# CY8C5888LTI_LP097 register map
File version: 0.1
Registers are 8-bit, read-write, no defined reset value unless marked. A register's access mark holds for its fields unless they carry their own. Offsets are from the block's base; [hi:lo] are bit positions; 'fields as' and 'values as' point back to an identical list.

## Encoder_4
Base 0x00000000
0x4000640A Encoder_4_COUNTER 24-bit — UDB.A0 - Current Counter Value
0x4000642A Encoder_4_PERIOD 24-bit — UDB.D0 - Assigned Period
0x4000643A Encoder_4_COMPARE 24-bit — UDB.D1 - Assigned Compare Value
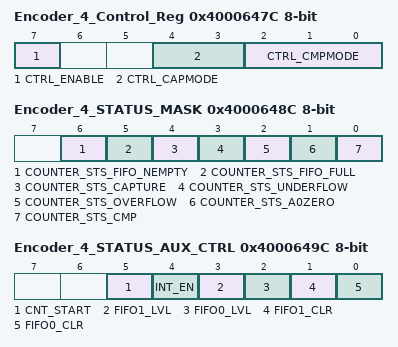
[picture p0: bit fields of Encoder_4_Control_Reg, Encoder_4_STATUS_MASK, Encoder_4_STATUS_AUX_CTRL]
0x4000647C Encoder_4_Control_Reg — UDB Control Register - Assigned Control Register Value
  [7] CTRL_ENABLE — Enable Counter
  [4:3] CTRL_CAPMODE — Capture mode
  [2:0] CTRL_CMPMODE — Compare mode
0x4000648C Encoder_4_STATUS_MASK — UDB Status bits Interrupt Mask Enable Register
  [6] COUNTER_STS_FIFO_NEMPTY — FIFO Not Empty Status
  [5] COUNTER_STS_FIFO_FULL — FIFO Full Status
  [4] COUNTER_STS_CAPTURE — Capture Status
  [3] COUNTER_STS_UNDERFLOW — Underflow status
  [2] COUNTER_STS_OVERFLOW — Overflow status
  [1] COUNTER_STS_A0ZERO — A0 Zero ouput status
  [0] COUNTER_STS_CMP — Compare output status
0x4000649C Encoder_4_STATUS_AUX_CTRL — UDB Auxilliary Control Register
  [5] CNT_START — FIFO0 clear
    0=E_CNT_START0 (Disable counter); 1=E_CNT_START1 (Enable counter)
  [4] INT_EN
    0=E_INT_EN0 (Interrupt disabled); 1=E_INT_EN1 (Interrupt enabled)
  [3] FIFO1_LVL — FIFO level
    0=E_FIFO_LVL_0 (FIFO LVL: input mode: FIFO not full; output mode: FIFO not empty); 1=E_FIFO_LVL_1 (FIFO LVL: input mode: FIFO at least 1/2 empty; output mode: FIFO at least 1/2 full)
  [2] FIFO0_LVL — FIFO level
    values as FIFO1_LVL
  [1] FIFO1_CLR — FIFO1 clear
    0=E_FIFO_CLR_0 (Normal FIFO operation); 1=E_FIFO_CLR_1 (Clear FIFO state)
  [0] FIFO0_CLR — FIFO0 clear
    values as FIFO1_CLR

## Encoder_5
Base 0x00000000
0x4000640D Encoder_5_COUNTER 24-bit — UDB.A0 - Current Counter Value
0x4000642D Encoder_5_PERIOD 24-bit — UDB.D0 - Assigned Period
0x4000643D Encoder_5_COMPARE 24-bit — UDB.D1 - Assigned Compare Value
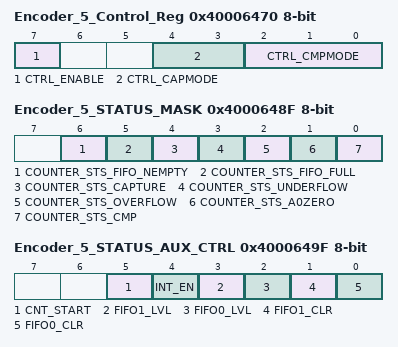
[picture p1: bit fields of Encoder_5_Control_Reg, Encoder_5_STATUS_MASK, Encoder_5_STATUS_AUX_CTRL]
0x40006470 Encoder_5_Control_Reg — UDB Control Register - Assigned Control Register Value
  [7] CTRL_ENABLE — Enable Counter
  [4:3] CTRL_CAPMODE — Capture mode
  [2:0] CTRL_CMPMODE — Compare mode
0x4000648F Encoder_5_STATUS_MASK — UDB Status bits Interrupt Mask Enable Register
  [6] COUNTER_STS_FIFO_NEMPTY — FIFO Not Empty Status
  [5] COUNTER_STS_FIFO_FULL — FIFO Full Status
  [4] COUNTER_STS_CAPTURE — Capture Status
  [3] COUNTER_STS_UNDERFLOW — Underflow status
  [2] COUNTER_STS_OVERFLOW — Overflow status
  [1] COUNTER_STS_A0ZERO — A0 Zero ouput status
  [0] COUNTER_STS_CMP — Compare output status
0x4000649F Encoder_5_STATUS_AUX_CTRL — UDB Auxilliary Control Register
  [5] CNT_START — FIFO0 clear
    0=E_CNT_START0 (Disable counter); 1=E_CNT_START1 (Enable counter)
  [4] INT_EN
    0=E_INT_EN0 (Interrupt disabled); 1=E_INT_EN1 (Interrupt enabled)
  [3] FIFO1_LVL — FIFO level
    0=E_FIFO_LVL_0 (FIFO LVL: input mode: FIFO not full; output mode: FIFO not empty); 1=E_FIFO_LVL_1 (FIFO LVL: input mode: FIFO at least 1/2 empty; output mode: FIFO at least 1/2 full)
  [2] FIFO0_LVL — FIFO level
    values as FIFO1_LVL
  [1] FIFO1_CLR — FIFO1 clear
    0=E_FIFO_CLR_0 (Normal FIFO operation); 1=E_FIFO_CLR_1 (Clear FIFO state)
  [0] FIFO0_CLR — FIFO0 clear
    values as FIFO1_CLR

## Encoder_3
Base 0x00000000
0x40006407 Encoder_3_COUNTER 24-bit — UDB.A0 - Current Counter Value
0x40006427 Encoder_3_PERIOD 24-bit — UDB.D0 - Assigned Period
0x40006437 Encoder_3_COMPARE 24-bit — UDB.D1 - Assigned Compare Value
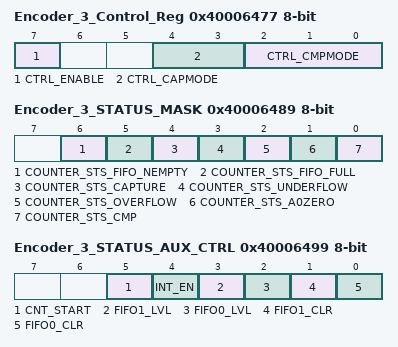
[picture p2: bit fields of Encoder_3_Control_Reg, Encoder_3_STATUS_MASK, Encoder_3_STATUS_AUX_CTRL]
0x40006477 Encoder_3_Control_Reg — UDB Control Register - Assigned Control Register Value
  [7] CTRL_ENABLE — Enable Counter
  [4:3] CTRL_CAPMODE — Capture mode
  [2:0] CTRL_CMPMODE — Compare mode
0x40006489 Encoder_3_STATUS_MASK — UDB Status bits Interrupt Mask Enable Register
  [6] COUNTER_STS_FIFO_NEMPTY — FIFO Not Empty Status
  [5] COUNTER_STS_FIFO_FULL — FIFO Full Status
  [4] COUNTER_STS_CAPTURE — Capture Status
  [3] COUNTER_STS_UNDERFLOW — Underflow status
  [2] COUNTER_STS_OVERFLOW — Overflow status
  [1] COUNTER_STS_A0ZERO — A0 Zero ouput status
  [0] COUNTER_STS_CMP — Compare output status
0x40006499 Encoder_3_STATUS_AUX_CTRL — UDB Auxilliary Control Register
  [5] CNT_START — FIFO0 clear
    0=E_CNT_START0 (Disable counter); 1=E_CNT_START1 (Enable counter)
  [4] INT_EN
    0=E_INT_EN0 (Interrupt disabled); 1=E_INT_EN1 (Interrupt enabled)
  [3] FIFO1_LVL — FIFO level
    0=E_FIFO_LVL_0 (FIFO LVL: input mode: FIFO not full; output mode: FIFO not empty); 1=E_FIFO_LVL_1 (FIFO LVL: input mode: FIFO at least 1/2 empty; output mode: FIFO at least 1/2 full)
  [2] FIFO0_LVL — FIFO level
    values as FIFO1_LVL
  [1] FIFO1_CLR — FIFO1 clear
    0=E_FIFO_CLR_0 (Normal FIFO operation); 1=E_FIFO_CLR_1 (Clear FIFO state)
  [0] FIFO0_CLR — FIFO0 clear
    values as FIFO1_CLR

## Encoder_1
Base 0x00000000
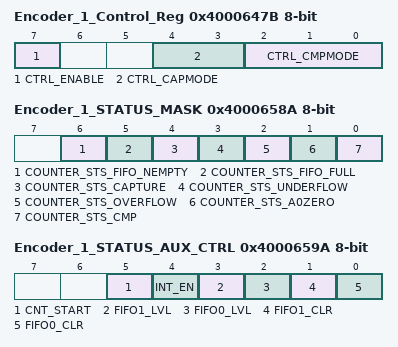
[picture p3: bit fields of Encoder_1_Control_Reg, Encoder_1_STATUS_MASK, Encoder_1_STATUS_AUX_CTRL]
0x4000647B Encoder_1_Control_Reg — UDB Control Register - Assigned Control Register Value
  [7] CTRL_ENABLE — Enable Counter
  [4:3] CTRL_CAPMODE — Capture mode
  [2:0] CTRL_CMPMODE — Compare mode
0x40006508 Encoder_1_COUNTER 24-bit — UDB.A0 - Current Counter Value
0x40006528 Encoder_1_PERIOD 24-bit — UDB.D0 - Assigned Period
0x40006538 Encoder_1_COMPARE 24-bit — UDB.D1 - Assigned Compare Value
0x4000658A Encoder_1_STATUS_MASK — UDB Status bits Interrupt Mask Enable Register
  [6] COUNTER_STS_FIFO_NEMPTY — FIFO Not Empty Status
  [5] COUNTER_STS_FIFO_FULL — FIFO Full Status
  [4] COUNTER_STS_CAPTURE — Capture Status
  [3] COUNTER_STS_UNDERFLOW — Underflow status
  [2] COUNTER_STS_OVERFLOW — Overflow status
  [1] COUNTER_STS_A0ZERO — A0 Zero ouput status
  [0] COUNTER_STS_CMP — Compare output status
0x4000659A Encoder_1_STATUS_AUX_CTRL — UDB Auxilliary Control Register
  [5] CNT_START — FIFO0 clear
    0=E_CNT_START0 (Disable counter); 1=E_CNT_START1 (Enable counter)
  [4] INT_EN
    0=E_INT_EN0 (Interrupt disabled); 1=E_INT_EN1 (Interrupt enabled)
  [3] FIFO1_LVL — FIFO level
    0=E_FIFO_LVL_0 (FIFO LVL: input mode: FIFO not full; output mode: FIFO not empty); 1=E_FIFO_LVL_1 (FIFO LVL: input mode: FIFO at least 1/2 empty; output mode: FIFO at least 1/2 full)
  [2] FIFO0_LVL — FIFO level
    values as FIFO1_LVL
  [1] FIFO1_CLR — FIFO1 clear
    0=E_FIFO_CLR_0 (Normal FIFO operation); 1=E_FIFO_CLR_1 (Clear FIFO state)
  [0] FIFO0_CLR — FIFO0 clear
    values as FIFO1_CLR

## Encoder_2
Base 0x00000000
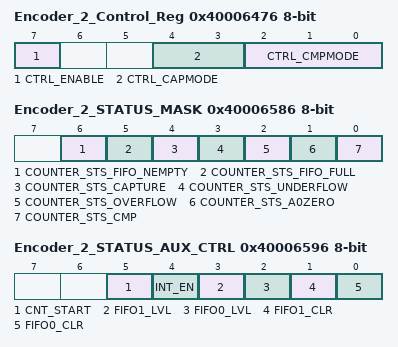
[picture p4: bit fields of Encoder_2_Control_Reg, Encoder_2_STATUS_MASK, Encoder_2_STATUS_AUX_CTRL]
0x40006476 Encoder_2_Control_Reg — UDB Control Register - Assigned Control Register Value
  [7] CTRL_ENABLE — Enable Counter
  [4:3] CTRL_CAPMODE — Capture mode
  [2:0] CTRL_CMPMODE — Compare mode
0x40006504 Encoder_2_COUNTER 24-bit — UDB.A0 - Current Counter Value
0x40006524 Encoder_2_PERIOD 24-bit — UDB.D0 - Assigned Period
0x40006534 Encoder_2_COMPARE 24-bit — UDB.D1 - Assigned Compare Value
0x40006586 Encoder_2_STATUS_MASK — UDB Status bits Interrupt Mask Enable Register
  [6] COUNTER_STS_FIFO_NEMPTY — FIFO Not Empty Status
  [5] COUNTER_STS_FIFO_FULL — FIFO Full Status
  [4] COUNTER_STS_CAPTURE — Capture Status
  [3] COUNTER_STS_UNDERFLOW — Underflow status
  [2] COUNTER_STS_OVERFLOW — Overflow status
  [1] COUNTER_STS_A0ZERO — A0 Zero ouput status
  [0] COUNTER_STS_CMP — Compare output status
0x40006596 Encoder_2_STATUS_AUX_CTRL — UDB Auxilliary Control Register
  [5] CNT_START — FIFO0 clear
    0=E_CNT_START0 (Disable counter); 1=E_CNT_START1 (Enable counter)
  [4] INT_EN
    0=E_INT_EN0 (Interrupt disabled); 1=E_INT_EN1 (Interrupt enabled)
  [3] FIFO1_LVL — FIFO level
    0=E_FIFO_LVL_0 (FIFO LVL: input mode: FIFO not full; output mode: FIFO not empty); 1=E_FIFO_LVL_1 (FIFO LVL: input mode: FIFO at least 1/2 empty; output mode: FIFO at least 1/2 full)
  [2] FIFO0_LVL — FIFO level
    values as FIFO1_LVL
  [1] FIFO1_CLR — FIFO1 clear
    0=E_FIFO_CLR_0 (Normal FIFO operation); 1=E_FIFO_CLR_1 (Clear FIFO state)
  [0] FIFO0_CLR — FIFO0 clear
    values as FIFO1_CLR
